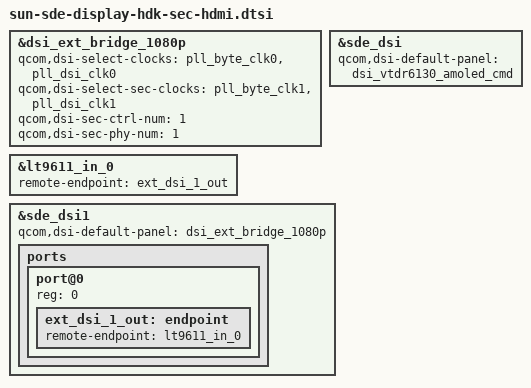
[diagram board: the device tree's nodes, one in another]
// SPDX-License-Identifier: BSD-3-Clause
/*
 * Copyright (c) Qualcomm Technologies, Inc. and/or its subsidiaries.
 */

#include "sun-sde-display-hdk.dtsi"

&dsi_ext_bridge_1080p {
	qcom,dsi-select-clocks = "pll_byte_clk0", "pll_dsi_clk0";
	qcom,dsi-select-sec-clocks = "pll_byte_clk1", "pll_dsi_clk1";
	qcom,dsi-sec-ctrl-num = <1>;
	qcom,dsi-sec-phy-num = <1>;
};

&sde_dsi {
	qcom,dsi-default-panel = <&dsi_vtdr6130_amoled_cmd>;
};

&lt9611_in_0 {
	remote-endpoint = <&ext_dsi_1_out>;
};

&sde_dsi1 {
	qcom,dsi-default-panel = <&dsi_ext_bridge_1080p>;
	ports {
		#address-cells = <1>;
		#size-cells = <0>;

		port@0 {
			reg = <0>;
			ext_dsi_1_out: endpoint {
				remote-endpoint = <&lt9611_in_0>;
			};
		};
	};
};
